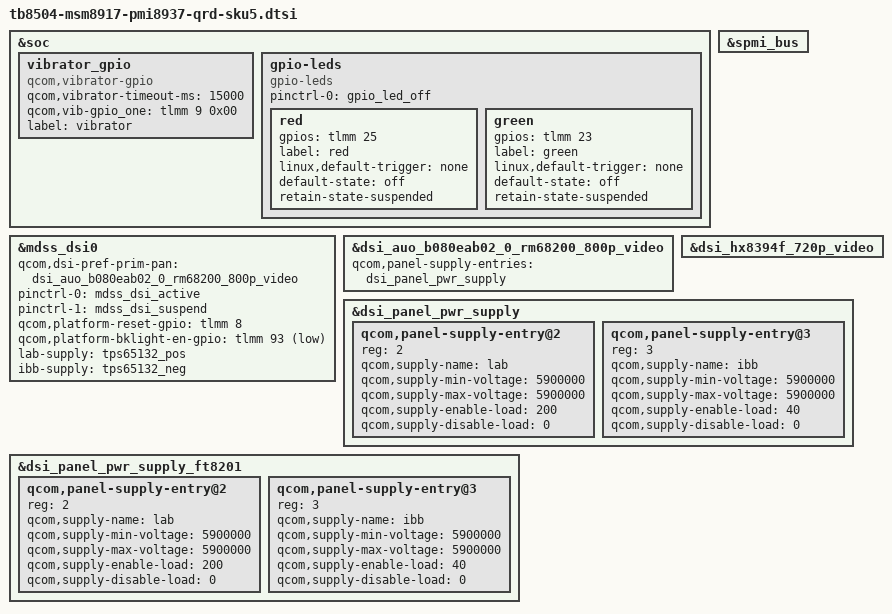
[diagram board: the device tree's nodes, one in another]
&soc {
	/delete-node/ qcom,camera-flash;
};

&spmi_bus {
	/delete-node/ qcom,pmi8937@2;
	/delete-node/ qcom,pmi8937@3;
};

&mdss_dsi0 {
	qcom,dsi-pref-prim-pan = <&dsi_auo_b080eab02_0_rm68200_800p_video>;
	pinctrl-names = "mdss_default", "mdss_sleep";
	pinctrl-0 = <&mdss_dsi_active>;
	pinctrl-1 = <&mdss_dsi_suspend>;

    //qcom,platform-te-gpio = <&tlmm 50 0>;
	qcom,platform-reset-gpio = <&tlmm 8 0>;
	qcom,platform-bklight-en-gpio = <&tlmm 93 1>;
    lab-supply = <&tps65132_pos>;
	ibb-supply = <&tps65132_neg>;

};

&dsi_auo_b080eab02_0_rm68200_800p_video {
	qcom,panel-supply-entries = <&dsi_panel_pwr_supply>;
};

&dsi_hx8394f_720p_video {
/delete-property/	qcom,esd-check-enabled;
/delete-property/	qcom,panel-supply-entries;
};


&soc {

	vibrator_gpio {//for vibrator
		compatible = "qcom,vibrator-gpio";
		qcom,vibrator-timeout-ms = <15000>;
		qcom,vib-gpio_one = <&tlmm 9 0x00>;
		label = "vibrator";
	};

	gpio-leds {
		compatible = "gpio-leds";
		status = "okay";
		pinctrl-names = "default";
		pinctrl-0 = <&gpio_led_off>;
			red {
				gpios = <&tlmm 25 0>;
				label = "red";
				linux,default-trigger = "none";
				default-state = "off";
				retain-state-suspended;
			};

			green {
				gpios = <&tlmm 23 0>;
				label = "green";
				linux,default-trigger = "none";
				default-state = "off";
				retain-state-suspended;
			};
	};
};


&dsi_panel_pwr_supply {
	qcom,panel-supply-entry@2 {
		reg = <2>;
		qcom,supply-name = "lab";
		qcom,supply-min-voltage = <5900000>;
		qcom,supply-max-voltage = <5900000>;
		qcom,supply-enable-load = <200>;
		qcom,supply-disable-load = <0>;
	};

	qcom,panel-supply-entry@3 {
		reg = <3>;
		qcom,supply-name = "ibb";
		qcom,supply-min-voltage = <5900000>;
		qcom,supply-max-voltage = <5900000>;
		qcom,supply-enable-load = <40>;
		qcom,supply-disable-load = <0>;
	};
};

&dsi_panel_pwr_supply_ft8201 {
	qcom,panel-supply-entry@2 {
		reg = <2>;
		qcom,supply-name = "lab";
		qcom,supply-min-voltage = <5900000>;
		qcom,supply-max-voltage = <5900000>;
		qcom,supply-enable-load = <200>;
		qcom,supply-disable-load = <0>;
	};

	qcom,panel-supply-entry@3 {
		reg = <3>;
		qcom,supply-name = "ibb";
		qcom,supply-min-voltage = <5900000>;
		qcom,supply-max-voltage = <5900000>;
		qcom,supply-enable-load = <40>;
		qcom,supply-disable-load = <0>;
	};
};
